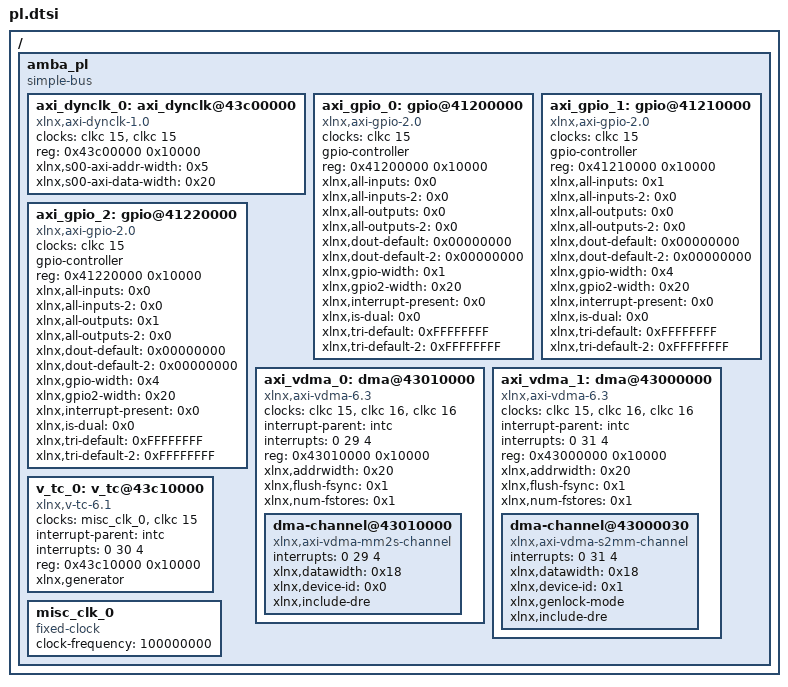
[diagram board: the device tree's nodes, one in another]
/*
 * CAUTION: This file is automatically generated by Xilinx.
 * Version:  
 * Today is: Wed Sep  9 06:03:22 2020
 */


/ {
	amba_pl: amba_pl {
		#address-cells = <1>;
		#size-cells = <1>;
		compatible = "simple-bus";
		ranges ;
		axi_dynclk_0: axi_dynclk@43c00000 {
			clock-names = "REF_CLK_I", "s00_axi_aclk";
			clocks = <&clkc 15>, <&clkc 15>;
			compatible = "xlnx,axi-dynclk-1.0";
			reg = <0x43c00000 0x10000>;
			xlnx,s00-axi-addr-width = <0x5>;
			xlnx,s00-axi-data-width = <0x20>;
		};
		axi_gpio_0: gpio@41200000 {
			#gpio-cells = <3>;
			clock-names = "s_axi_aclk";
			clocks = <&clkc 15>;
			compatible = "xlnx,axi-gpio-2.0", "xlnx,xps-gpio-1.00.a";
			gpio-controller ;
			reg = <0x41200000 0x10000>;
			xlnx,all-inputs = <0x0>;
			xlnx,all-inputs-2 = <0x0>;
			xlnx,all-outputs = <0x0>;
			xlnx,all-outputs-2 = <0x0>;
			xlnx,dout-default = <0x00000000>;
			xlnx,dout-default-2 = <0x00000000>;
			xlnx,gpio-width = <0x1>;
			xlnx,gpio2-width = <0x20>;
			xlnx,interrupt-present = <0x0>;
			xlnx,is-dual = <0x0>;
			xlnx,tri-default = <0xFFFFFFFF>;
			xlnx,tri-default-2 = <0xFFFFFFFF>;
		};
		axi_gpio_1: gpio@41210000 {
			#gpio-cells = <3>;
			clock-names = "s_axi_aclk";
			clocks = <&clkc 15>;
			compatible = "xlnx,axi-gpio-2.0", "xlnx,xps-gpio-1.00.a";
			gpio-controller ;
			reg = <0x41210000 0x10000>;
			xlnx,all-inputs = <0x1>;
			xlnx,all-inputs-2 = <0x0>;
			xlnx,all-outputs = <0x0>;
			xlnx,all-outputs-2 = <0x0>;
			xlnx,dout-default = <0x00000000>;
			xlnx,dout-default-2 = <0x00000000>;
			xlnx,gpio-width = <0x4>;
			xlnx,gpio2-width = <0x20>;
			xlnx,interrupt-present = <0x0>;
			xlnx,is-dual = <0x0>;
			xlnx,tri-default = <0xFFFFFFFF>;
			xlnx,tri-default-2 = <0xFFFFFFFF>;
		};
		axi_gpio_2: gpio@41220000 {
			#gpio-cells = <3>;
			clock-names = "s_axi_aclk";
			clocks = <&clkc 15>;
			compatible = "xlnx,axi-gpio-2.0", "xlnx,xps-gpio-1.00.a";
			gpio-controller ;
			reg = <0x41220000 0x10000>;
			xlnx,all-inputs = <0x0>;
			xlnx,all-inputs-2 = <0x0>;
			xlnx,all-outputs = <0x1>;
			xlnx,all-outputs-2 = <0x0>;
			xlnx,dout-default = <0x00000000>;
			xlnx,dout-default-2 = <0x00000000>;
			xlnx,gpio-width = <0x4>;
			xlnx,gpio2-width = <0x20>;
			xlnx,interrupt-present = <0x0>;
			xlnx,is-dual = <0x0>;
			xlnx,tri-default = <0xFFFFFFFF>;
			xlnx,tri-default-2 = <0xFFFFFFFF>;
		};
		axi_vdma_0: dma@43010000 {
			#dma-cells = <1>;
			clock-names = "s_axi_lite_aclk", "m_axi_mm2s_aclk", "m_axis_mm2s_aclk";
			clocks = <&clkc 15>, <&clkc 16>, <&clkc 16>;
			compatible = "xlnx,axi-vdma-6.3", "xlnx,axi-vdma-1.00.a";
			interrupt-names = "mm2s_introut";
			interrupt-parent = <&intc>;
			interrupts = <0 29 4>;
			reg = <0x43010000 0x10000>;
			xlnx,addrwidth = <0x20>;
			xlnx,flush-fsync = <0x1>;
			xlnx,num-fstores = <0x1>;
			dma-channel@43010000 {
				compatible = "xlnx,axi-vdma-mm2s-channel";
				interrupts = <0 29 4>;
				xlnx,datawidth = <0x18>;
				xlnx,device-id = <0x0>;
				xlnx,include-dre ;
			};
		};
		axi_vdma_1: dma@43000000 {
			#dma-cells = <1>;
			clock-names = "s_axi_lite_aclk", "m_axi_s2mm_aclk", "s_axis_s2mm_aclk";
			clocks = <&clkc 15>, <&clkc 16>, <&clkc 16>;
			compatible = "xlnx,axi-vdma-6.3", "xlnx,axi-vdma-1.00.a";
			interrupt-names = "s2mm_introut";
			interrupt-parent = <&intc>;
			interrupts = <0 31 4>;
			reg = <0x43000000 0x10000>;
			xlnx,addrwidth = <0x20>;
			xlnx,flush-fsync = <0x1>;
			xlnx,num-fstores = <0x1>;
			dma-channel@43000030 {
				compatible = "xlnx,axi-vdma-s2mm-channel";
				interrupts = <0 31 4>;
				xlnx,datawidth = <0x18>;
				xlnx,device-id = <0x1>;
				xlnx,genlock-mode ;
				xlnx,include-dre ;
			};
		};
		v_tc_0: v_tc@43c10000 {
			clock-names = "clk", "s_axi_aclk";
			clocks = <&misc_clk_0>, <&clkc 15>;
			compatible = "xlnx,v-tc-6.1", "xlnx,v-tc-6.1";
			interrupt-names = "irq";
			interrupt-parent = <&intc>;
			interrupts = <0 30 4>;
			reg = <0x43c10000 0x10000>;
			xlnx,generator ;
		};
		misc_clk_0: misc_clk_0 {
			#clock-cells = <0>;
			clock-frequency = <100000000>;
			compatible = "fixed-clock";
		};
	};
};
